# cslr_uart_001 register map
Vendor: Texas Instruments
Peripheral module from a debugger description file.
Registers are 32-bit, access not given, reset 0x0 unless marked. A register's access mark holds for its fields unless they carry their own. Offsets are as the file gives them; lines under a group give offsets from that group; [hi:lo] are bit positions; {n}, {i} and the like mark numbered series; 'fields as' and 'values as' point back to an identical list; <NAME> marks a mode.

## UART — Universal Asynchronous Receive Transmit
0x00 RBR — Receiver Buffer Register
  [7:0] DATA ro — Received data
0x00 THR — Transmitter Holding Register
  [7:0] DATA wo — Data to transmit
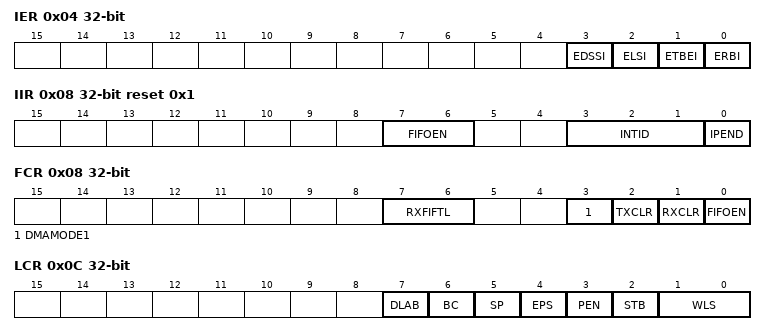
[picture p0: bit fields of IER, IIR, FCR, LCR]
0x04 IER — Interrupt Enable Register
  [all] fields
    0=DISABLE; 1=ENABLE
  [3] EDSSI rw — Enable Modem Status Interrupt
  [2] ELSI rw — Enable Receiver Line Status Interrupt
  [1] ETBEI rw — Enable Transmitter Holding Register Empty Interrupt
  [0] ERBI rw — Enable Receiver Data Available Interrupt and Character Timeout indication Interrupt
0x08 IIR reset 0x1 — Interrupt Identification Register
  [7:6] FIFOEN ro — FIFOs Enabled Always 00b in Non-FIFO mode Set to 11b when bit 0 of the FCR register is set
  [3:1] INTID ro — Encodes the different types of interrupt
    0=MODSTAT (Modem Status (Priority 4) Lowest); 1=THRE (THR Empty (Priority 3)); 2=RDA (Received Data Available (Priority 2)); 3=RLS (Receiver Line Status (Priority 1) Highest); 6=CTI (Character Timeout Indication (Priority 2))
  [0] IPEND ro — Interrupt Pending This bit is used either in a hardwire prioritized (nirq) or polled interrupt system
    1=NONE (No interrupts pending)
0x08 FCR — FIFO Control Register
  [7:6] RXFIFTL wo — Receiver FIFO Trigger Level (In bytes)
    0=CHAR1 (1 byte); 1=CHAR4 (4 byte); 2=CHAR8 (8 byte); 3=CHAR14 (14 byte)
  [3] DMAMODE1 wo — Setting this bit selects MODE 1 for DMA, provided FIFOs are enabled
    0=DISABLE (Disable DMA); 1=ENABLE (Enables MODE1)
  [2] TXCLR wo — Setting this bit clears the transmitter FIFO and resets the transmitter FIFO counter. The shift register is not cleared. The 1 that is written to this bit position is self-clearing
    1=CLR (Clears Tx FIFO)
  [1] RXCLR wo — Setting this bit resets the receiver FIFO counter. The shift register is not cleared. The 1 that is written to this bit position is self-clearing
    1=CLR (Clears Rx FIFO)
  [0] FIFOEN wo — Setting this bit enables the transmitter and receiver FIFOs. This bit must be set when other FCR bits are written to or they are not programmed. Clearing this bit clears the FIFO counters
    0=DISABLE (Disable FIFOs); 1=ENABLE (Enable FIFOs)
0x0C LCR — Line Control Register
  [7] DLAB rw — Divisor Latch Access Bit This bit must be set to access the divisor latches of the baud generator during a read or write operation This bit must be cleared to access the receiver buffer register, the transmitter holding register, or the interrupt enable register
  [6] BC rw — Break Control Bit
    0=DISABLE (Break condition is disabled); 1=ENABLE (Break condition is transmitted to the receiving UART)
  [5] SP rw — Stick Parity Bit When this bit is set and even parity is selected, the parity bit is transmitted and checked as cleared When this bit is set and odd parity is selected, the parity bit is transmitted and checked as set When this bit is cleared, stick parity is disabled
  [4] EPS rw — Even Parity Select When this bit is set and parity is enabled, even parity is selected (an even number of logic 1s is transmitted or checked in the data and parity bits) When this bit is cleared and parity is enabled, odd parity is selected (an odd number of logic 1s is transmitted or checked)
  [3] PEN rw — Parity Enable 0: no parity bit is transmitted or checked 1: a parity bit is generated in transmitted data and is checked in received data between the last data word bit and the first stop bit
  [2] STB rw — Number of Stop Bits Generated This bit specifies either one, one and a half, or two stop bits in each transmitted character. This bit is combined with the word length bits (LCR[1] and LCR[0]) determine the number of stop bits. The receiver clocks only the first stop bit regardless of the number of stop bits selected -------------------------------------------------------------------------------------------- Bit 2 Word Length Number of Stop Bits Generated -------------------------------------------------------------------------------------------- 0 Any word length 1 1 5 bits 1.5 1 6 bits 2 1 7 bits 2 1 8 bits 2
  [1:0] WLS rw — Word Length Select Number of bits in each transmitted or received serial character
    {v}=BITS{v+5} ({v+5} bits) (v=0..3)
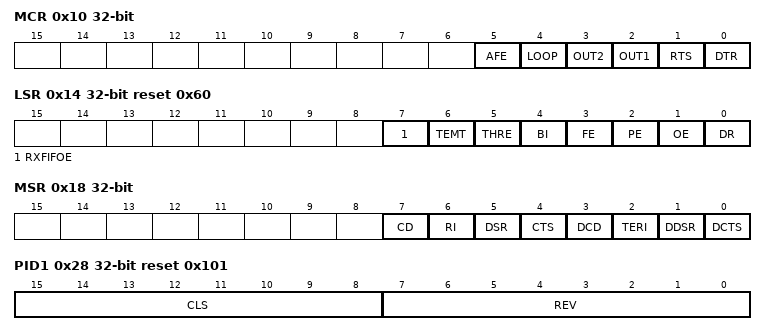
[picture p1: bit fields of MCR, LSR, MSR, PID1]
0x10 MCR — Modem Control Register
  [5] AFE rw — Auto Flow Control Enable When this bit is set, the autoflow control is enabled The autoflow control can be configured by setting bit 1 and 5 of the MCR ---------------------------------------------------------------------- Bit 5 Bit 1 Autoflow Control Configuration ---------------------------------------------------------------------- 1 1 Auto-rts and auto-cts enabled 1 0 Auto-cts only enabled 0 X Auto-rts and auto-cts disabled
    0=DISABLE (Disable AFC); 1=ENABLE (Enable AFC)
  [4] LOOP rw — Loop Mode Bit for the diagnostic testing of loop back feature
    0=DISABLE (Disable loop back mode); 1=ENABLE (Enable loop back mode)
  [3] OUT2 rw — OUT2 control bit
    0=HIGH (The associated output is forced high); 1=LOW (The associated output is forced low)
  [2] OUT1 rw — OUT1 control bit
    values as OUT2
  [1] RTS rw — RTS control bit
    0=HIGH (The associated output is forced high); 0=DISABLE (Auto-rts is disabled); 1=ENABLE (Auto-rts is enabled); 1=LOW (The associated output is forced low)
  [0] DTR rw — DTR control bit
    values as OUT2
0x14 LSR reset 0x60 — Line Status Register
  [7] RXFIFOE ro — Error in Receiver FIFO In the non-FIFO mode, this bit is set when there is a parity error, framing error, or break indicator in the receiver buffer register (RBR). It is cleared when the CPU reads the erroneous data In the FIFO mode, this bit is set when there is at least one parity error, framing error, or break indicator in the FIFO. It is cleared when the CPU reads the erroneous data and there are no more errors in the FIFO
  [6] TEMT ro — Transmitter empty (TEMT) indicator bit This bit is set when both the THR and the TSR are empty. It is cleared when either the THR or the TSR contains a data character In the FIFO mode, this bit is set when both the transmitter FIFO and the shift register are empty
  [5] THRE ro — Transmitter holding register empty (THRE) indicator bit This bit is set whenever the THR is empty, indicating that the UART is ready to accept a new character. If the THRE interrupt is enabled when this bit is set, an interrupt is generated. The THRE bit is set when the contents of the THR are transferred to the TSR. This bit is cleared at the same time when the CPU loads the THR In the FIFO mode, this bit is set when the transmitter FIFO is empty, and it is cleared when at least one byte is loaded into the FIFO
  [4] BI ro — Break indicator bit This bit is set whenever the receive data input was held low for longer than a full-word transmission time. A full-word transmission time is defined as the total time to transmit the start, data, parity and stop bits. This bit is cleared after the CPU reads the erroneous data in the non- FIFO mode In the FIFO mode, this error is associated with the particular character in the FIFO to which it applies. This error is revealed to the CPU when its associated character is at the top of the FIFO. This bit is cleared after the CPU reads the erroneous data and the next data to be read from the FIFO has no parity error
  [3] FE ro — Frame error bit This bit is set whenever the receive data character does not have a valid stop bit. This bit is cleared after the CPU reads the erroneous data in the non-FIFO mode In the FIFO mode, this error is associated with the particular character in the FIFO to which it applies. This error is revealed to the CPU when its associated character is at the top of the FIFO. This bit is cleared after the CPU reads the erroneous data and the next data to be read from the FIFO has no parity error The UART will try to resynchronize after a framing error. To accomplish this, it is assumed that the framing error is due to the next start bit, so it samples this start bit twice and then accepts the input data
  [2] PE ro — Parity error bit This bit is set whenever the parity of the receive data character does not match the parity selected in the LCR[4]. This bit is cleared after the CPU reads the erroneous data in the non- FIFO mode In the FIFO mode, this error is associated with the particular character in the FIFO to which it applies. This error is revealed to the CPU when its associated character is at the top of the FIFO. This bit is cleared after the CPU reads the erroneous data and the next data to be read from the FIFO has no parity error
  [1] OE ro — Overrun error bit This bit is set whenever a character is written to the RBR before the previous character was read by the CPU, in so doing the previous character is lost. This bit is cleared every time the CPU reads the contents of the LSR In the FIFO mode, if data continues to fill the FIFO beyond the trigger level, an overrun error occurs only after the FIFO is full and the next character has been completely received in the shift register. An overrun error is indicated to the CPU as soon as it happens. The character in the shift register is overwritten, but it is not transferred to the FIFO
  [0] DR ro — Data ready (DR) bit This bit is set whenever a complete incoming character has been received and transferred into the RBR or the FIFO This bit is cleared by reading all of the data in the RBR or the FIFO
0x18 MSR — Modem Status Register
  [7] CD ro — Complement of the Carrier Detect input When the UART is in the diagnostic test mode (loopback mode MCR[4] = 1), this bit is equal to the MCR bit 3 (OUT2)
  [6] RI ro — Complement of the Ring Indicator input When the UART is in the diagnostic test mode (loopback mode MCR[4] = 1), this bit is equal to the MCR bit 2 (OUT1)
  [5] DSR ro — Complement of the Data Set Ready input When the UART is in the diagnostic test mode (loopback mode MCR[4] = 1), this bit is equal to the MCR bit 0 (DTR)
  [4] CTS ro — Complement of the Clear To Send input When the UART is in the diagnostic test mode (loopback mode MCR[4] = 1), this bit is equal to the MCR bit 1 (RTS)
  [3] DCD ro — Change in DCD indicator bit DCD indicates that the DCD input has changed state since the last time it was read by the CPU. When DCD is set and the modem status interrupt is enabled, a modem status interrupt is generated
  [2] TERI ro — Trailing edge of RI (TERI) indicator bit TERI indicates that the RI input has changed from a low to a high. When TERI is set and the modem status interrupt is enabled, a modem status interrupt is generated
  [1] DDSR ro — Change in DSR indicator bit DDSR indicates that the DSR input has changed state since the last time it was read by the CPU. When DDSR is set and the modem status interrupt is enabled, a modem status interrupt is generated
  [0] DCTS ro — Change in CTS indicator bit DCTS indicates that the CTS input has changed state since the last time it was read by the CPU. When DCTS is set (autoflow control is not enabled and the modem status interrupt is enabled), a modem status interrupt is generated. When autoflow control is enabled, no interrupt is generated
0x1C SCR — Scratch Register
  [7:0] DATA rw — Intended for the programmer's use as a scratch pad in the sense that it temporarily holds the programmer's data without affecting any other UART operation
0x20 DLL 8-bit rw — Divisor Latch (LSB)
  [7:0] DLL — LSB of 16-bit divisor for generation of the baud clock in the baud rate generator
0x24 DLH 8-bit rw — Divisor Latch (MSB)
  [7:0] DLH — MSB of 16-bit divisor for generation of the baud clock in the baud rate generator
0x28 PID1 reset 0x101 — Peripheral ID Register 1 (Class/Revision)
  [15:8] CLS ro — Class of Peripheral
  [7:0] REV ro — Revision level of the UART
0x2C PID2 reset 0x4 — Peripheral ID Register 2 (Type)
  [7:0] TYP ro — Type of peripheral
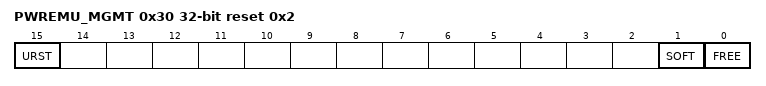
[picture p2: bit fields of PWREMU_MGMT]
0x30 PWREMU_MGMT reset 0x2 — Power Management and Emulation Register
  [15] URST rw — UART Reset bit Resets and enables the receiver and transmitter
    0=RESET (The receiver and transmitter are disabled and in reset state); 1=ENABLE (The receiver and transmitter are enabled)
  [1] SOFT rw — This bit is always 1. Writing this bit doesn't affect this value
  [0] FREE rw — This bit determines emulation mode functionality of the UART. When FREE is 0, the UART stop immediately if a transmission isn't in progress. If a transmission is in progress, the UART stops after completion of the one word transmission. In suspended mode, the UART can handle vbus request, but doesn't generate any interrupt and event
    0=STOP (UART stops immediately); 1=RUN (UART runs free)
